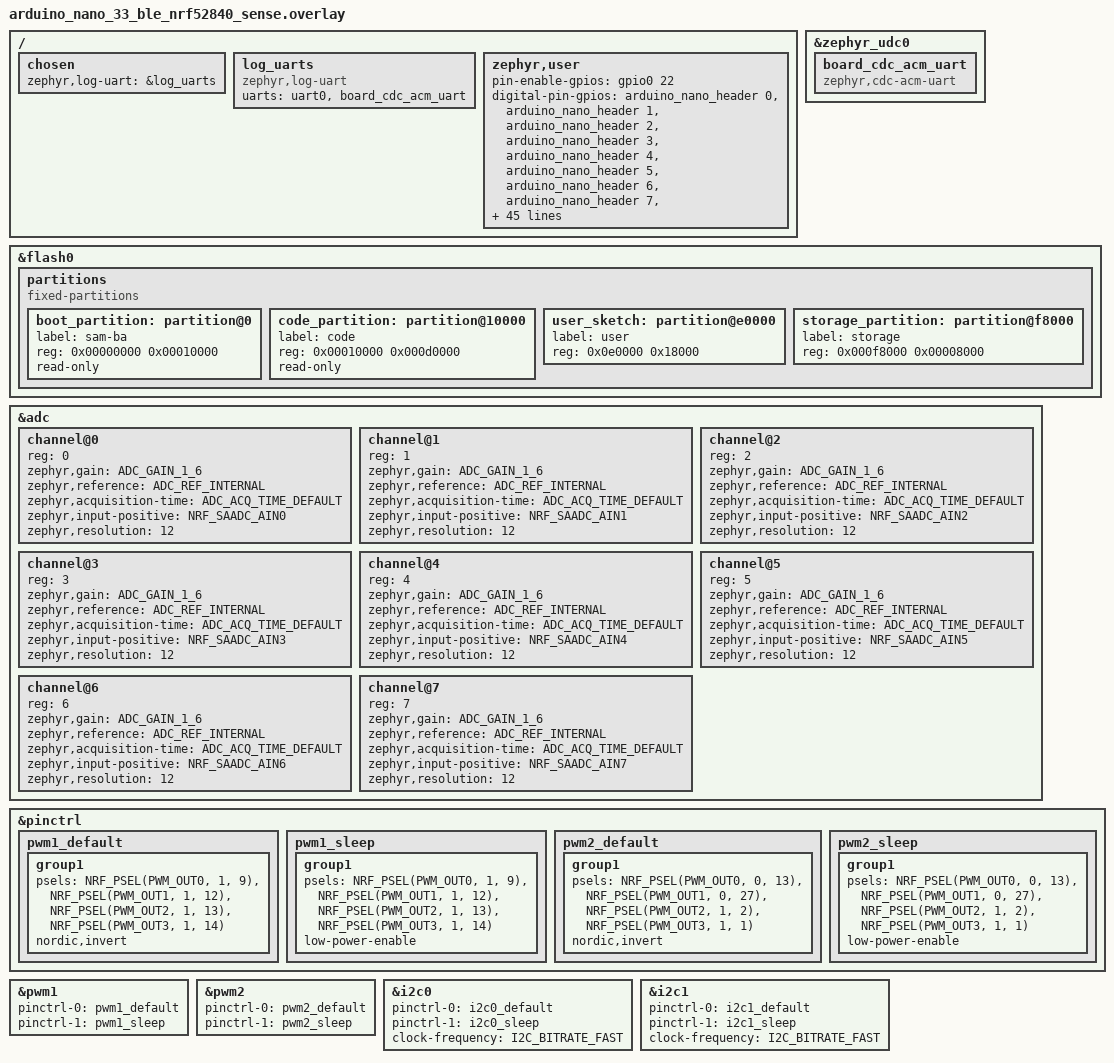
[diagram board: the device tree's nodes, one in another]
&zephyr_udc0 {
	board_cdc_acm_uart: board_cdc_acm_uart {
		compatible = "zephyr,cdc-acm-uart";
		status = "okay";
	};
};

&flash0 {
	partitions {
		compatible = "fixed-partitions";
		#address-cells = <1>;
		#size-cells = <1>;

		boot_partition: partition@0 {
			label = "sam-ba";
			reg = <0x00000000 0x00010000>;
			read-only;
		};

		code_partition: partition@10000 {
			label = "code";
			reg = <0x00010000 0x000d0000>;
			read-only;
		};

		user_sketch: partition@e0000 {
			label = "user";
			reg = <0x0e0000 0x18000>;
		};

		/*
		 * The flash starting at 0x000f8000 and ending at
		 * 0x000fffff is reserved for use by the application.
		 *
		 * Storage partition will be used by FCB/LittleFS/NVS
		 * if enabled.
		 */
		storage_partition: partition@f8000 {
			label = "storage";
			reg = <0x000f8000 0x00008000>;
		};
	};
};

/{
	chosen {
		zephyr,log-uart = &log_uarts;
	};

	log_uarts: log_uarts {
		compatible = "zephyr,log-uart";
		uarts = <&uart0 &board_cdc_acm_uart>;
	};
};


/ {
	zephyr,user {
		pin-enable-gpios = <&gpio0 22 GPIO_ACTIVE_HIGH>;

		digital-pin-gpios = <&arduino_nano_header 0 0>,
				    <&arduino_nano_header 1 0>,
				    <&arduino_nano_header 2 0>,
				    <&arduino_nano_header 3 0>,
				    <&arduino_nano_header 4 0>,
				    <&arduino_nano_header 5 0>,
				    <&arduino_nano_header 6 0>,
				    <&arduino_nano_header 7 0>,
				    <&arduino_nano_header 8 0>,
				    <&arduino_nano_header 9 0>,
				    <&arduino_nano_header 10 0>,
				    <&arduino_nano_header 11 0>,
				    <&arduino_nano_header 12 0>,
				    <&arduino_nano_header 13 0>,
				    <&arduino_nano_header 14 0>, /* D14 / A0 */
				    <&arduino_nano_header 15 0>,
				    <&arduino_nano_header 16 0>,
				    <&arduino_nano_header 17 0>,
				    <&arduino_nano_header 18 0>, /* D18 / A4 / I2C-SDA */
				    <&arduino_nano_header 19 0>, /* D19 / A5 / I2C-SCL */
				    <&arduino_nano_header 20 0>,
				    <&arduino_nano_header 21 0>,
				    <&gpio0 24 0>,	/* D22 LED R */
				    <&gpio0 16 0>,	/* D23 LED G */
				    <&gpio0 6 0>,	/* D24 LED B */
				    <&gpio1 9 0>,	/* D25 LED PWR */
				    <&gpio0 19 0>,	/* D26 INT APDS */
				    <&gpio0 17 0>,	/* D27 PDM PWR */
				    <&gpio0 26 0>,	/* D28 PDM CLK */
				    <&gpio0 25 0>,	/* D29 PDM DIN */
				    <&gpio0 14 0>,	/* D30 SDA2 */
				    <&gpio0 15 0>,	/* D31 SCL2 */
				    <&gpio1 0 0>,	/* D32 I2C_PULL */
				    <&gpio0 22 0>;	/* D33 VDD_ENV_ENABLE */

		pwm-pin-gpios =	    <&arduino_nano_header 3 0>,
				    <&arduino_nano_header 5 0>,
				    <&arduino_nano_header 6 0>,
				    <&arduino_nano_header 13 0>,
				    <&arduino_nano_header 9 0>,
				    <&arduino_nano_header 10 0>,
				    <&arduino_nano_header 11 0>;

		adc-pin-gpios =	    <&arduino_nano_header 14 0>,
				    <&arduino_nano_header 15 0>,
				    <&arduino_nano_header 16 0>,
				    <&arduino_nano_header 17 0>,
				    <&arduino_nano_header 18 0>,
				    <&arduino_nano_header 19 0>,
				    <&arduino_nano_header 20 0>,
				    <&arduino_nano_header 21 0>;

		builtin-led-gpios = <&arduino_nano_header 13 0>;

		pwms =	<&pwm1 1 255 PWM_POLARITY_NORMAL>,
			<&pwm1 2 255 PWM_POLARITY_NORMAL>,
			<&pwm1 3 255 PWM_POLARITY_NORMAL>,
			<&pwm2 0 255 PWM_POLARITY_NORMAL>,
			<&pwm2 1 255 PWM_POLARITY_NORMAL>,
			<&pwm2 2 255 PWM_POLARITY_NORMAL>,
			<&pwm2 3 255 PWM_POLARITY_NORMAL>;

		io-channels =	<&adc 2>,
				<&adc 3>,
				<&adc 6>,
				<&adc 5>,
				<&adc 7>,
				<&adc 0>,
				<&adc 4>,
				<&adc 1>;

		serials = <&board_cdc_acm_uart>, <&uart0>;
		cdc-acm = <&board_cdc_acm_uart>;
		i2cs = <&arduino_nano_i2c>, <&i2c1>;
	};
};

&adc {
	#address-cells = <1>;
	#size-cells = <0>;

	channel@0 {
		reg = <0>;
		zephyr,gain = "ADC_GAIN_1_6";
		zephyr,reference = "ADC_REF_INTERNAL";
		zephyr,acquisition-time = <ADC_ACQ_TIME_DEFAULT>;
		zephyr,input-positive = <NRF_SAADC_AIN0>; /* P0.02 */
		zephyr,resolution = <12>;
	};

	channel@1 {
		reg = <1>;
		zephyr,gain = "ADC_GAIN_1_6";
		zephyr,reference = "ADC_REF_INTERNAL";
		zephyr,acquisition-time = <ADC_ACQ_TIME_DEFAULT>;
		zephyr,input-positive = <NRF_SAADC_AIN1>; /* P0.03 */
		zephyr,resolution = <12>;
	};

	channel@2 {
		reg = <2>;
		zephyr,gain = "ADC_GAIN_1_6";
		zephyr,reference = "ADC_REF_INTERNAL";
		zephyr,acquisition-time = <ADC_ACQ_TIME_DEFAULT>;
		zephyr,input-positive = <NRF_SAADC_AIN2>; /* P0.04 */
		zephyr,resolution = <12>;
	};

	channel@3 {
		reg = <3>;
		zephyr,gain = "ADC_GAIN_1_6";
		zephyr,reference = "ADC_REF_INTERNAL";
		zephyr,acquisition-time = <ADC_ACQ_TIME_DEFAULT>;
		zephyr,input-positive = <NRF_SAADC_AIN3>; /* P0.05 */
		zephyr,resolution = <12>;
	};

	channel@4 {
		reg = <4>;
		zephyr,gain = "ADC_GAIN_1_6";
		zephyr,reference = "ADC_REF_INTERNAL";
		zephyr,acquisition-time = <ADC_ACQ_TIME_DEFAULT>;
		zephyr,input-positive = <NRF_SAADC_AIN4>; /* P0.28 */
		zephyr,resolution = <12>;
	};

	channel@5 {
		reg = <5>;
		zephyr,gain = "ADC_GAIN_1_6";
		zephyr,reference = "ADC_REF_INTERNAL";
		zephyr,acquisition-time = <ADC_ACQ_TIME_DEFAULT>;
		zephyr,input-positive = <NRF_SAADC_AIN5>; /* P0.29 */
		zephyr,resolution = <12>;
	};

	channel@6 {
		reg = <6>;
		zephyr,gain = "ADC_GAIN_1_6";
		zephyr,reference = "ADC_REF_INTERNAL";
		zephyr,acquisition-time = <ADC_ACQ_TIME_DEFAULT>;
		zephyr,input-positive = <NRF_SAADC_AIN6>; /* P0.30 */
		zephyr,resolution = <12>;
	};

	channel@7 {
		reg = <7>;
		zephyr,gain = "ADC_GAIN_1_6";
		zephyr,reference = "ADC_REF_INTERNAL";
		zephyr,acquisition-time = <ADC_ACQ_TIME_DEFAULT>;
		zephyr,input-positive = <NRF_SAADC_AIN7>; /* P0.31 */
		zephyr,resolution = <12>;
	};
};

&pinctrl {
	pwm1_default: pwm1_default {
		group1 {
			psels = <NRF_PSEL(PWM_OUT0, 1, 9)>, /* keep original config */
				<NRF_PSEL(PWM_OUT1, 1, 12)>,
				<NRF_PSEL(PWM_OUT2, 1, 13)>,
				<NRF_PSEL(PWM_OUT3, 1, 14)>;
				nordic,invert;
		};
	};

	pwm1_sleep: pwm1_sleep {
		group1 {
			psels = <NRF_PSEL(PWM_OUT0, 1, 9)>, /* keep original config */
				<NRF_PSEL(PWM_OUT1, 1, 12)>,
				<NRF_PSEL(PWM_OUT2, 1, 13)>,
				<NRF_PSEL(PWM_OUT3, 1, 14)>;
				low-power-enable;
		};
	};

	pwm2_default: pwm2_default {
		group1 {
			psels = <NRF_PSEL(PWM_OUT0, 0, 13)>, /* keep original config */
				<NRF_PSEL(PWM_OUT1, 0, 27)>,
				<NRF_PSEL(PWM_OUT2, 1, 2)>,
				<NRF_PSEL(PWM_OUT3, 1, 1)>;
				nordic,invert;
		};
	};

	pwm2_sleep: pwm2_sleep {
		group1 {
			psels = <NRF_PSEL(PWM_OUT0, 0, 13)>, /* keep original config */
				<NRF_PSEL(PWM_OUT1, 0, 27)>,
				<NRF_PSEL(PWM_OUT2, 1, 2)>,
				<NRF_PSEL(PWM_OUT3, 1, 1)>;
				low-power-enable;
		};
	};
};

&pwm1 {
	status = "okay";
	pinctrl-0 = <&pwm1_default>;
	pinctrl-1 = <&pwm1_sleep>;
	pinctrl-names = "default", "sleep";
};

&pwm2 {
	status = "okay";
	pinctrl-0 = <&pwm2_default>;
	pinctrl-1 = <&pwm2_sleep>;
	pinctrl-names = "default", "sleep";
};

&i2c0 {
	status = "okay";
	pinctrl-0 = <&i2c0_default>;
	pinctrl-1 = <&i2c0_sleep>;
	pinctrl-names = "default", "sleep";
	clock-frequency = <I2C_BITRATE_FAST>;
};

&i2c1 {
	status = "okay";
	pinctrl-0 = <&i2c1_default>;
	pinctrl-1 = <&i2c1_sleep>;
	pinctrl-names = "default", "sleep";
	clock-frequency = <I2C_BITRATE_FAST>;
};

